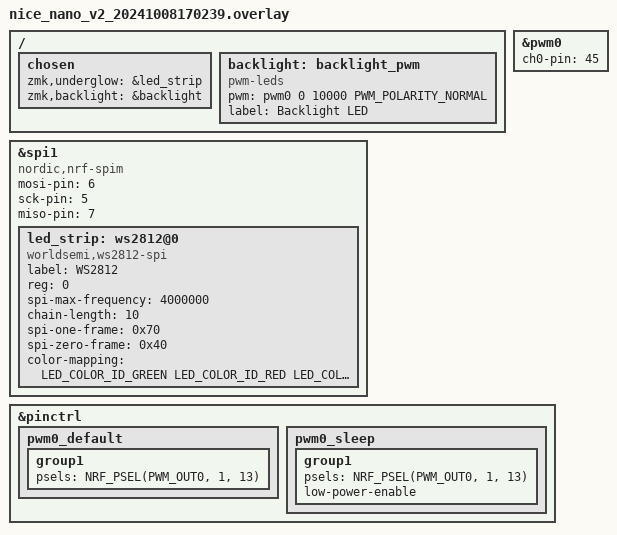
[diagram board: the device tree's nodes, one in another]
#include <dt-bindings/led/led.h>

&spi1 {
    compatible = "nordic,nrf-spim";
    status = "okay";
    mosi-pin = <6>;
    // Unused pins, needed for SPI definition, but not used by the ws2812 driver
    sck-pin = <5>;
    miso-pin = <7>;

    led_strip: ws2812@0 {
        compatible = "worldsemi,ws2812-spi";
        label = "WS2812";

        /* SPI */
        reg = <0>; /* ignored, but necessary for SPI bindings */
        spi-max-frequency = <4000000>;

        /* WS2812 */
        chain-length = <10>; /* number of LEDs */
        spi-one-frame = <0x70>;
        spi-zero-frame = <0x40>;
        color-mapping = <LED_COLOR_ID_GREEN
                         LED_COLOR_ID_RED
                         LED_COLOR_ID_BLUE>;
    };
};

/ {
    chosen {
        zmk,underglow = &led_strip;
    };
};

&pwm0 {
    status = "okay";
    ch0-pin = <45>; // Use the appropriate GPIO pin for your backlight
};

/ {
    backlight: backlight_pwm {
        compatible = "pwm-leds";
        pwm = <&pwm0 0 10000 PWM_POLARITY_NORMAL>;
        label = "Backlight LED";
    };
};

/ {
    chosen {
        zmk,backlight = &backlight;
    };
};

&pinctrl {
    // Other pinctrl definitions for other hardware
    pwm0_default: pwm0_default {
        group1 {
            psels = <NRF_PSEL(PWM_OUT0, 1, 13)>;
        };
    };
    pwm0_sleep: pwm0_sleep {
        group1 {
            psels = <NRF_PSEL(PWM_OUT0, 1, 13)>;
            low-power-enable;
        };
    };
};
